# GPIOMUX_INTRTR0_CFG register map
Vendor: Texas Instruments
Peripheral module from a debugger description file (folder J7ES).
Registers are 32-bit, read-only, reset values left out (the file's numbers can be read two ways) unless marked. A register's access mark holds for its fields unless they carry their own. Offsets are as the file gives them; lines under a group give offsets from that group; [hi:lo] are bit positions; {n}, {i} and the like mark numbered series; 'fields as' and 'values as' point back to an identical list; <NAME> marks a mode.

## GPIOMUX_INTRTR0_CFG
0x00 GPIOMUX_INTRTR0_PID — Identification register.
  [31:0] REV — TI internal data. Identifies revision of peripheral.
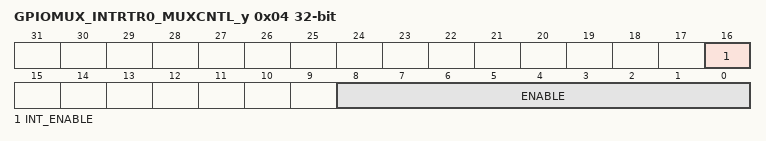
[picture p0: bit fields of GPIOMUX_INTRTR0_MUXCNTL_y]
0x04 GPIOMUX_INTRTR0_MUXCNTL_y access per field — Interrupt mux control register. Offset = 4h + (y * 4h); where y = 0h to 3Fh.
  [16] INT_ENABLE rw — Interrupt output enable for interrupt N
  [8:0] ENABLE rw — Mux control for interrupt N
